VERSION ""

NS_ :

BS_:

BU_:

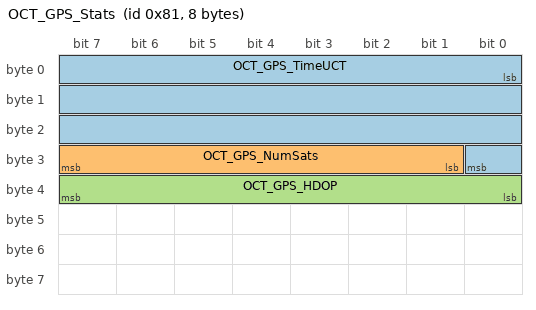
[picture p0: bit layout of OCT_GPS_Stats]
BO_ 129 OCT_GPS_Stats: 8 Vector__XXX
 SG_ OCT_GPS_TimeUCT : 0|25@1+ (0.01,0) [0|24000000] "" Vector__XXX
 SG_ OCT_GPS_NumSats : 25|7@1+ (1,0) [0|99] "" Vector__XXX
 SG_ OCT_GPS_HDOP : 32|8@1+ (1,0) [0|256] "" Vector__XXX

BO_ 128 OCT_GPS_LatLong: 8 Vector__XXX
 SG_ OCT_GPS_Longitude : 0|32@1- (0.0001,0) [0|1809999999] "" Vector__XXX
 SG_ OCT_GPS_Latitude : 32|31@1- (0.0001,0) [0|909999999] "" Vector__XXX

CM_ BO_ 129 "Horizontal Dilution of Precision (HDOP), number of connected satellites, and UCT Time from satellites.";
CM_ BO_ 128 "Latitude and Longitude values in fixed point decimal format.";
BA_DEF_  "BusType" STRING ;
BA_DEF_ BO_  "OCT_PDU_ID" INT 0 0;
BA_DEF_ BO_  "OCT_ENABLE" ENUM  "False","True";
BA_DEF_DEF_  "BusType" "CAN";
BA_DEF_DEF_  "OCT_PDU_ID" 0;
BA_DEF_DEF_  "OCT_ENABLE" "False";
BA_ "OCT_PDU_ID" BO_ 129 8;
BA_ "OCT_ENABLE" BO_ 129 1;
BA_ "OCT_PDU_ID" BO_ 128 7;
BA_ "OCT_ENABLE" BO_ 128 1;
